# nrf9120 register map
Vendor: Nordic Semiconductor; Series: nrf91; File version: 1
CPU: CM33 r0p4, little endian, MPU, FPU, 3 interrupt priority bits, 69 interrupts
Registers are 32-bit, read-write, reset 0x0 unless marked. A register's access mark holds for its fields unless they carry their own. Offsets are from the block's base; [hi:lo] are bit positions; lines under a group give offsets from that group; 'fields as' and 'values as' point back to an identical list.

## I2S_NS — Inter-IC Sound 0
Base 0x40028000
Same registers: I2S_S 0x50028000
0x00 TASKS_START wo — Starts continuous I2S transfer. Also starts MCK generator when this is enabled.
  [0] TASKS_START
    1=Trigger task
0x04 TASKS_STOP wo — Stops I2S transfer. Also stops MCK generator. Triggering this task will cause the STOPPED event to be generated.
  [0] TASKS_STOP
    1=Trigger task
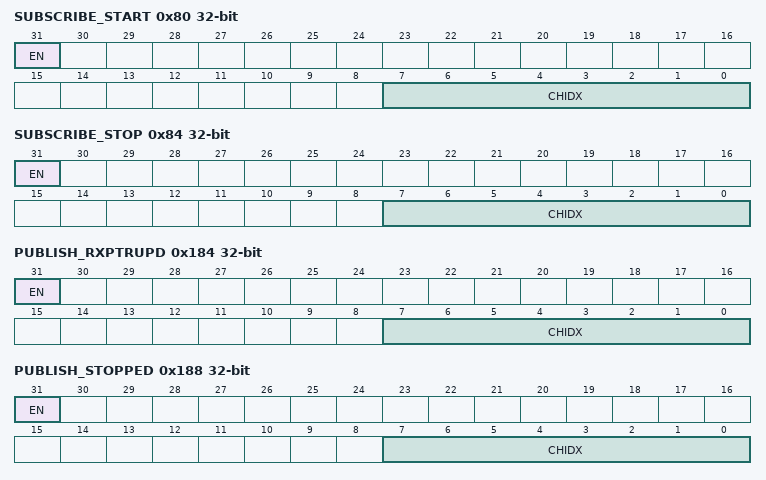
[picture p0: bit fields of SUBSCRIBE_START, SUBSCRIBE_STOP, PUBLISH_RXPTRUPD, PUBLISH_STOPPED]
0x80 SUBSCRIBE_START — Subscribe configuration for task START
  [31] EN
    0=Disabled (Disable subscription); 1=Enabled (Enable subscription)
  [7:0] CHIDX — DPPI channel that task START will subscribe to
0x84 SUBSCRIBE_STOP — Subscribe configuration for task STOP
  [31] EN
    values as SUBSCRIBE_START.EN
  [7:0] CHIDX — DPPI channel that task STOP will subscribe to
0x104 EVENTS_RXPTRUPD — The RXD.PTR register has been copied to internal double-buffers. When the I2S module is started and RX is enabled, this event will be generated for every RXTXD.MAXCNT words that are received on the SDIN pin.
  [0] EVENTS_RXPTRUPD
    0=NotGenerated (Event not generated); 1=Generated (Event generated)
0x108 EVENTS_STOPPED — I2S transfer stopped.
  [0] EVENTS_STOPPED
    values as EVENTS_RXPTRUPD.EVENTS_RXPTRUPD
0x114 EVENTS_TXPTRUPD — The TDX.PTR register has been copied to internal double-buffers. When the I2S module is started and TX is enabled, this event will be generated for every RXTXD.MAXCNT words that are sent on the SDOUT pin.
  [0] EVENTS_TXPTRUPD
    values as EVENTS_RXPTRUPD.EVENTS_RXPTRUPD
0x184 PUBLISH_RXPTRUPD — Publish configuration for event RXPTRUPD
  [31] EN
    0=Disabled (Disable publishing); 1=Enabled (Enable publishing)
  [7:0] CHIDX — DPPI channel that event RXPTRUPD will publish to
0x188 PUBLISH_STOPPED — Publish configuration for event STOPPED
  [31] EN
    values as PUBLISH_RXPTRUPD.EN
  [7:0] CHIDX — DPPI channel that event STOPPED will publish to
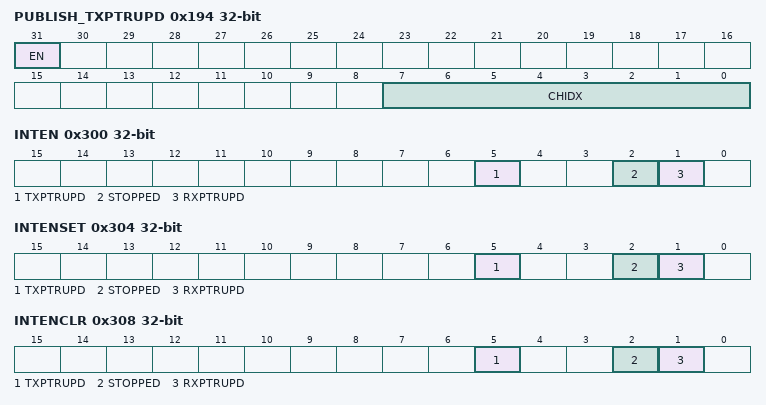
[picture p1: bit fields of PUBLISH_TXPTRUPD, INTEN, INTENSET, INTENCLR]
0x194 PUBLISH_TXPTRUPD — Publish configuration for event TXPTRUPD
  [31] EN
    values as PUBLISH_RXPTRUPD.EN
  [7:0] CHIDX — DPPI channel that event TXPTRUPD will publish to
0x300 INTEN — Enable or disable interrupt
  [all] fields
    0=Disabled; 1=Enabled
  [5] TXPTRUPD — Enable or disable interrupt for event TXPTRUPD
  [2] STOPPED — Enable or disable interrupt for event STOPPED
  [1] RXPTRUPD — Enable or disable interrupt for event RXPTRUPD
0x304 INTENSET — Enable interrupt
  [all] fields
    on read: 0=Disabled (Read: Disabled); 1=Enabled (Read: Enabled) | on write: 1=Set (Enable)
  [5] TXPTRUPD — Write '1' to enable interrupt for event TXPTRUPD
  [2] STOPPED — Write '1' to enable interrupt for event STOPPED
  [1] RXPTRUPD — Write '1' to enable interrupt for event RXPTRUPD
0x308 INTENCLR — Disable interrupt
  [all] fields
    on read: 0=Disabled (Read: Disabled); 1=Enabled (Read: Enabled) | on write: 1=Clear (Disable)
  [5] TXPTRUPD — Write '1' to disable interrupt for event TXPTRUPD
  [2] STOPPED — Write '1' to disable interrupt for event STOPPED
  [1] RXPTRUPD — Write '1' to disable interrupt for event RXPTRUPD
0x500 ENABLE — Enable I2S module.
  [0] ENABLE
    0=Disabled; 1=Enabled
0x504 CONFIG group — Unspecified
  0x00 MODE — I2S mode.
    [0] MODE
      0=Master mode. SCK and LRCK generated from internal master clcok (MCK) and output on pins defined by PSEL.xxx.; 1=Slave mode. SCK and LRCK generated by external master and received on pins defined by PSEL.xxx
  0x04 RXEN — Reception (RX) enable.
    [0] RXEN
      0=Disabled (Reception disabled and now data will be written to the RXD.PTR address.); 1=Enabled (Reception enabled.)
  0x08 TXEN reset 0x1 — Transmission (TX) enable.
    [0] TXEN
      0=Disabled (Transmission disabled and now data will be read from the RXD.TXD address.); 1=Enabled (Transmission enabled.)
  0x0C MCKEN reset 0x1 — Master clock generator enable.
    [0] MCKEN
      0=Disabled (Master clock generator disabled and PSEL.MCK not connected(available as GPIO).); 1=Enabled (Master clock generator running and MCK output on PSEL.MCK.)
  0x10 MCKFREQ reset 0x20000000 — Master clock generator frequency.
    [31:0] MCKFREQ
      0x20000000=32MDIV8 (32 MHz / 8 = 4.0 MHz); 0x18000000=32MDIV10 (32 MHz / 10 = 3.2 MHz); 0x16000000=32MDIV11 (32 MHz / 11 = 2.9090909 MHz); 0x11000000=32MDIV15 (32 MHz / 15 = 2.1333333 MHz); 0x10000000=32MDIV16 (32 MHz / 16 = 2.0 MHz); 0xC000000=32MDIV21 (32 MHz / 21 = 1.5238095); 0xB000000=32MDIV23 (32 MHz / 23 = 1.3913043 MHz); 0x8800000=32MDIV30 (32 MHz / 30 = 1.0666667 MHz); 0x8400000=32MDIV31 (32 MHz / 31 = 1.0322581 MHz); 0x8000000=32MDIV32 (32 MHz / 32 = 1.0 MHz); 0x6000000=32MDIV42 (32 MHz / 42 = 0.7619048 MHz); 0x4100000=32MDIV63 (32 MHz / 63 = 0.5079365 MHz); 0x20C0000=32MDIV125 (32 MHz / 125 = 0.256 MHz)
  0x14 RATIO reset 0x6 — MCK / LRCK ratio.
    [3:0] RATIO
      0=32X (LRCK = MCK / 32); 1=48X (LRCK = MCK / 48); 2=64X (LRCK = MCK / 64); 3=96X (LRCK = MCK / 96); 4=128X (LRCK = MCK / 128); 5=192X (LRCK = MCK / 192); 6=256X (LRCK = MCK / 256); 7=384X (LRCK = MCK / 384); 8=512X (LRCK = MCK / 512)
  0x18 SWIDTH reset 0x1 — Sample width.
    [1:0] SWIDTH
      0=8Bit; 1=16Bit; 2=24Bit
  0x1C ALIGN — Alignment of sample within a frame.
    [0] ALIGN
      0=Left-aligned; 1=Right-aligned
  0x20 FORMAT — Frame format.
    [0] FORMAT
      0=I2S (Original I2S format.); 1=Aligned (Alternate (left- or right-aligned) format.)
  0x24 CHANNELS — Enable channels.
    [1:0] CHANNELS
      0=Stereo; 1=Left only; 2=Right only
0x538 RXD group — Unspecified
  0x00 PTR — Receive buffer RAM start address.
    [31:0] PTR — Receive buffer Data RAM start address. When receiving, words containing samples will be written to this address. This address is a word aligned Data RAM address.
0x540 TXD group — Unspecified
  0x00 PTR — Transmit buffer RAM start address.
    [31:0] PTR — Transmit buffer Data RAM start address. When transmitting, words containing samples will be fetched from this address. This address is a word aligned Data RAM address.
0x550 RXTXD group — Unspecified
  0x00 MAXCNT — Size of RXD and TXD buffers.
    [13:0] MAXCNT — Size of RXD and TXD buffers in number of 32 bit words.
0x560 PSEL group — Unspecified
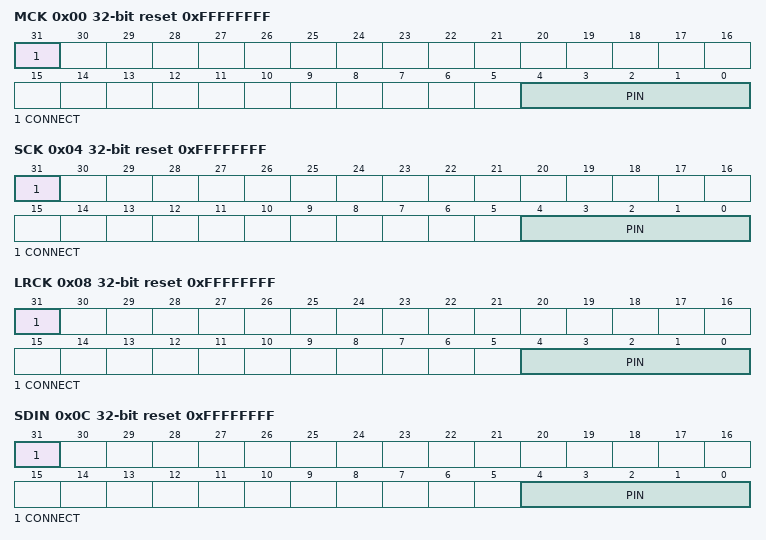
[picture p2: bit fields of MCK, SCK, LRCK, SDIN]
  0x00 MCK reset 0xFFFFFFFF — Pin select for MCK signal.
    [31] CONNECT — Connection
      1=Disconnected; 0=Connected
    [4:0] PIN — Pin number
  0x04 SCK reset 0xFFFFFFFF — Pin select for SCK signal.
    fields as PSEL.MCK
  0x08 LRCK reset 0xFFFFFFFF — Pin select for LRCK signal.
    fields as PSEL.MCK
  0x0C SDIN reset 0xFFFFFFFF — Pin select for SDIN signal.
    fields as PSEL.MCK
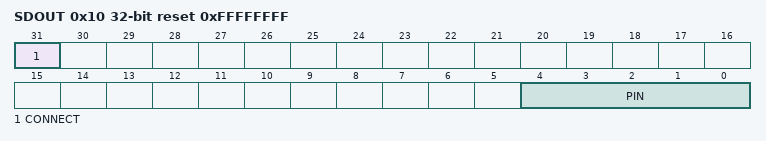
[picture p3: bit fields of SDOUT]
  0x10 SDOUT reset 0xFFFFFFFF — Pin select for SDOUT signal.
    fields as PSEL.MCK
